VERSION ""

NS_ :

BS_:

BU_: EBCM EON CAM PCM EPS VSA SCM BDY XXX

BO_ 57 XXX_1: 3 XXX

BO_ 148 XXX_2: 8 XXX

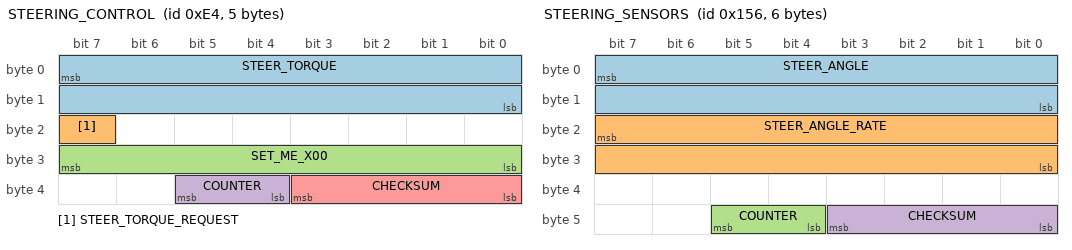
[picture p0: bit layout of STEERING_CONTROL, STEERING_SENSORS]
BO_ 228 STEERING_CONTROL: 5 CAM
 SG_ STEER_TORQUE : 7|16@0- (1,0) [-3840|3840] "" EPS
 SG_ STEER_TORQUE_REQUEST : 23|1@0+ (1,0) [0|1] "" EPS
 SG_ SET_ME_X00 : 31|8@0+ (1,0) [0|0] "" EPS
 SG_ COUNTER : 37|2@0+ (1,0) [0|3] "" EPS
 SG_ CHECKSUM : 35|4@0+ (1,0) [0|3] "" EPS

BO_ 229 XXX_3: 4 XXX

BO_ 316 GAS_PEDAL: 8 PCM
 SG_ CAR_GAS : 39|8@0+ (1,0) [0|255] "" EON

BO_ 342 STEERING_SENSORS: 6 EPS
 SG_ STEER_ANGLE : 7|16@0- (-0.1,0) [-500|500] "deg" EON
 SG_ STEER_ANGLE_RATE : 23|16@0- (1,0) [-3000|3000] "deg/s" EON
 SG_ COUNTER : 45|2@0+ (1,0) [0|3] "" EON
 SG_ CHECKSUM : 43|4@0+ (1,0) [0|3] "" EON

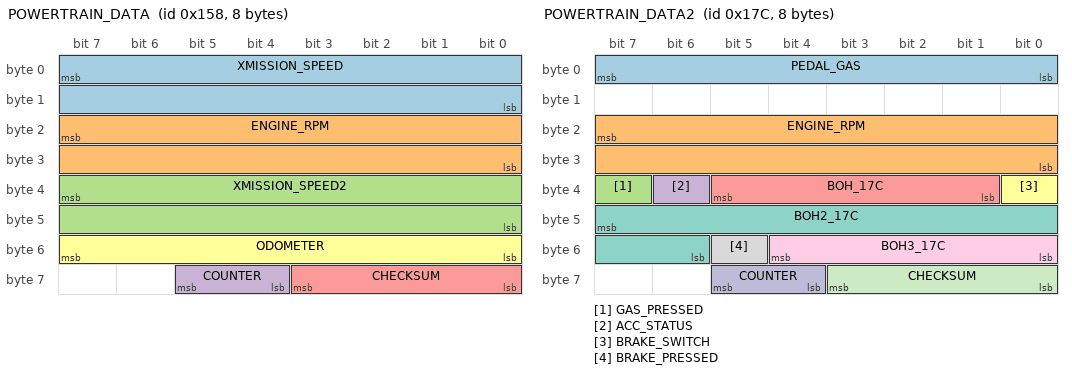
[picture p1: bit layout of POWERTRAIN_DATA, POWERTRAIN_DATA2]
BO_ 344 POWERTRAIN_DATA: 8 PCM
 SG_ XMISSION_SPEED : 7|16@0+ (0.002759506,0) [0|70] "m/s" EON
 SG_ ENGINE_RPM : 23|16@0+ (1,0) [0|15000] "rpm" EON
 SG_ XMISSION_SPEED2 : 39|16@0+ (0.002759506,0) [0|70] "m/s" EON
 SG_ COUNTER : 61|2@0+ (1,0) [0|3] "" EON
 SG_ CHECKSUM : 59|4@0+ (1,0) [0|3] "" EON
 SG_ ODOMETER : 55|8@0+ (1,0) [0|255] "" XXX

BO_ 380 POWERTRAIN_DATA2: 8 PCM
 SG_ PEDAL_GAS : 7|8@0+ (1,0) [0|255] "" EON
 SG_ ENGINE_RPM : 23|16@0+ (1,0) [0|15000] "rpm" EON
 SG_ GAS_PRESSED : 39|1@0+ (1,0) [0|1] "" EON
 SG_ ACC_STATUS : 38|1@0+ (1,0) [0|1] "rpm" EON
 SG_ BOH_17C : 37|5@0+ (1,0) [0|1] "rpm" EON
 SG_ BRAKE_SWITCH : 32|1@0+ (1,0) [0|1] "rpm" EON
 SG_ BOH2_17C : 47|10@0+ (1,0) [0|1] "rpm" EON
 SG_ BRAKE_PRESSED : 53|1@0+ (1,0) [0|1] "" EON
 SG_ BOH3_17C : 52|5@0+ (1,0) [0|1] "rpm" EON
 SG_ COUNTER : 61|2@0+ (1,0) [0|3] "" EON
 SG_ CHECKSUM : 59|4@0+ (1,0) [0|3] "" EON

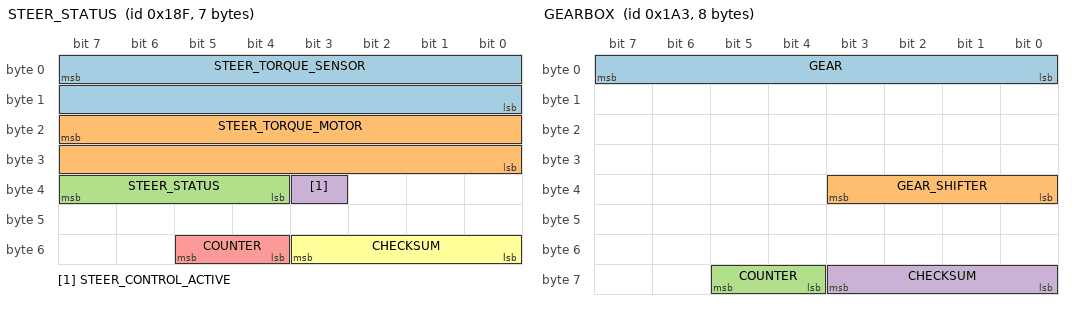
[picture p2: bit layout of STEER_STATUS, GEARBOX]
BO_ 399 STEER_STATUS: 7 EPS
 SG_ STEER_TORQUE_SENSOR : 7|16@0- (1,0) [-31000|31000] "tbd" EON
 SG_ STEER_TORQUE_MOTOR : 23|16@0- (1,0) [-31000|31000] "tbd" EON
 SG_ STEER_STATUS : 39|4@0+ (1,0) [0|15] "" EON
 SG_ STEER_CONTROL_ACTIVE : 35|1@0+ (1,0) [0|1] "" EON
 SG_ COUNTER : 53|2@0+ (1,0) [0|3] "" EON
 SG_ CHECKSUM : 51|4@0+ (1,0) [0|3] "" EON

BO_ 411 XXX_4: 5 XXX

BO_ 419 GEARBOX: 8 PCM
 SG_ GEAR : 7|8@0+ (1,0) [0|256] "" EON
 SG_ GEAR_SHIFTER : 35|4@0+ (1,0) [0|15] "" EON
 SG_ COUNTER : 61|2@0+ (1,0) [0|3] "" EON
 SG_ CHECKSUM : 59|4@0+ (1,0) [0|3] "" EON

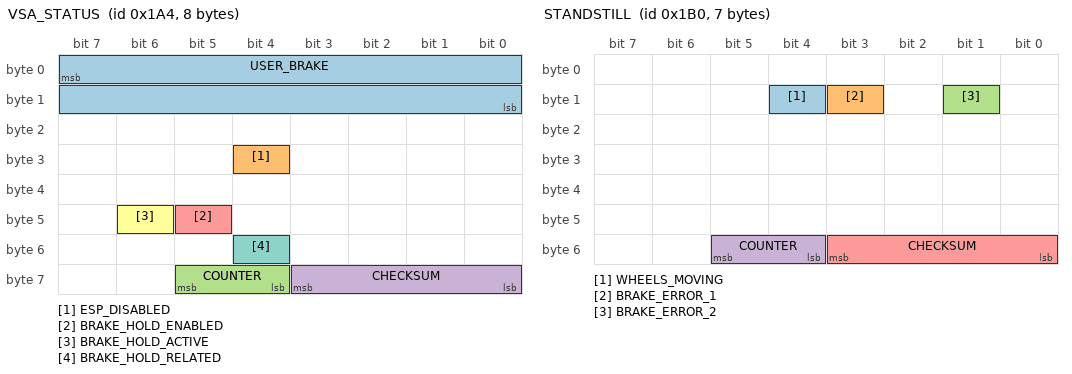
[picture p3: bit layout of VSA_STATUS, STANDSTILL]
BO_ 420 VSA_STATUS: 8 VSA
 SG_ USER_BRAKE : 7|16@0+ (0.015625,-1.609375) [0|1000] "" EON
 SG_ ESP_DISABLED : 28|1@0+ (1,0) [0|1] "" EON
 SG_ COUNTER : 61|2@0+ (1,0) [0|3] "" EON
 SG_ CHECKSUM : 59|4@0+ (1,0) [0|3] "" EON
 SG_ BRAKE_HOLD_ENABLED : 45|1@0+ (1,0) [0|1] "" XXX
 SG_ BRAKE_HOLD_ACTIVE : 46|1@0+ (1,0) [0|1] "" XXX
 SG_ BRAKE_HOLD_RELATED : 52|1@0+ (1,0) [0|1] "" XXX

BO_ 427 XXX_5: 3 XXX

BO_ 432 STANDSTILL: 7 VSA
 SG_ WHEELS_MOVING : 12|1@0+ (1,0) [0|1] "" EON
 SG_ BRAKE_ERROR_1 : 11|1@0+ (1,0) [0|1] "" EON
 SG_ BRAKE_ERROR_2 : 9|1@0+ (1,0) [0|1] "" EON
 SG_ COUNTER : 53|2@0+ (1,0) [0|3] "" EON
 SG_ CHECKSUM : 51|4@0+ (1,0) [0|3] "" EON

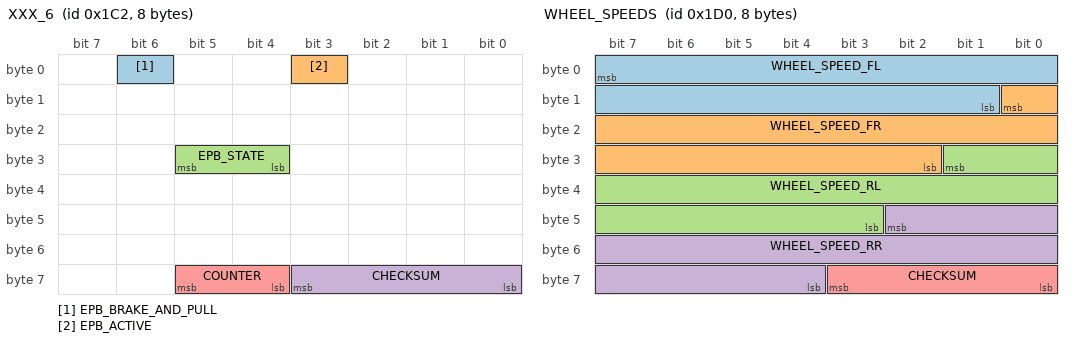
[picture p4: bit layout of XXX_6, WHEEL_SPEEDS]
BO_ 450 XXX_6: 8 XXX
 SG_ EPB_BRAKE_AND_PULL : 6|1@0+ (1,0) [0|1] "" XXX
 SG_ EPB_ACTIVE : 3|1@0+ (1,0) [0|1] "" XXX
 SG_ EPB_STATE : 29|2@0+ (1,0) [0|1] "" XXX
 SG_ CHECKSUM : 59|4@0+ (1,0) [0|15] "" XXX
 SG_ COUNTER : 61|2@0+ (1,0) [0|3] "" XXX

BO_ 463 XXX_7: 8 XXX

BO_ 464 WHEEL_SPEEDS: 8 VSA
 SG_ WHEEL_SPEED_FL : 7|15@0+ (0.002759506,0) [0|70] "m/s" EON
 SG_ WHEEL_SPEED_FR : 8|15@0+ (0.002759506,0) [0|70] "m/s" EON
 SG_ WHEEL_SPEED_RL : 25|15@0+ (0.002759506,0) [0|70] "m/s" EON
 SG_ WHEEL_SPEED_RR : 42|15@0+ (0.002759506,0) [0|70] "m/s" EON
 SG_ CHECKSUM : 59|4@0+ (1,0) [0|3] "" EON

BO_ 476 XXX_8: 4 XXX

BO_ 490 VEHICLE_DYNAMICS: 8 VSA
 SG_ LONG_ACCEL : 23|16@0- (0.0015384,0) [-20|20] "m/s2" EON

BO_ 506 BRAKE_COMMAND: 8 CAM
 SG_ COMPUTER_BRAKE : 7|10@0+ (0.003906248,0) [0|1] "" EBCM
 SG_ ZEROS_BOH : 13|5@0+ (1,0) [0|1] "" EBCM
 SG_ COMPUTER_BRAKE_REQUEST : 8|1@0+ (1,0) [0|1] "" EBCM
 SG_ CRUISE_BOH2 : 23|3@0+ (1,0) [0|1] "" EBCM
 SG_ CRUISE_OVERRIDE : 20|1@0+ (1,0) [0|1] "" EBCM
 SG_ CRUISE_BOH3 : 19|1@0+ (1,0) [0|1] "" EBCM
 SG_ CRUISE_FAULT_CMD : 18|1@0+ (1,0) [0|1] "" EBCM
 SG_ CRUISE_CANCEL_CMD : 17|1@0+ (1,0) [0|1] "" EBCM
 SG_ COMPUTER_BRAKE_REQUEST_2 : 16|1@0+ (1,0) [0|1] "" EBCM
 SG_ CRUISE_BOH4 : 31|8@0+ (1,0) [0|1] "" EBCM
 SG_ BRAKE_LIGHTS : 39|1@0+ (1,0) [0|1] "" EBCM
 SG_ CRUISE_BOH5 : 38|7@0+ (1,0) [0|1] "" EBCM
 SG_ CHIME : 47|3@0+ (1,0) [0|7] "" EBCM
 SG_ CRUISE_BOH6 : 44|1@0+ (1,0) [0|1] "" EBCM
 SG_ FCW : 43|2@0+ (1,0) [0|3] "" EBCM
 SG_ CRUISE_BOH7 : 41|10@0+ (1,0) [0|0] "" EBCM
 SG_ COUNTER : 61|2@0+ (1,0) [0|3] "" EBCM
 SG_ CHECKSUM : 59|4@0+ (1,0) [0|3] "" EBCM

BO_ 542 XXX_9: 7 XXX

BO_ 545 XXX_10: 4 XXX

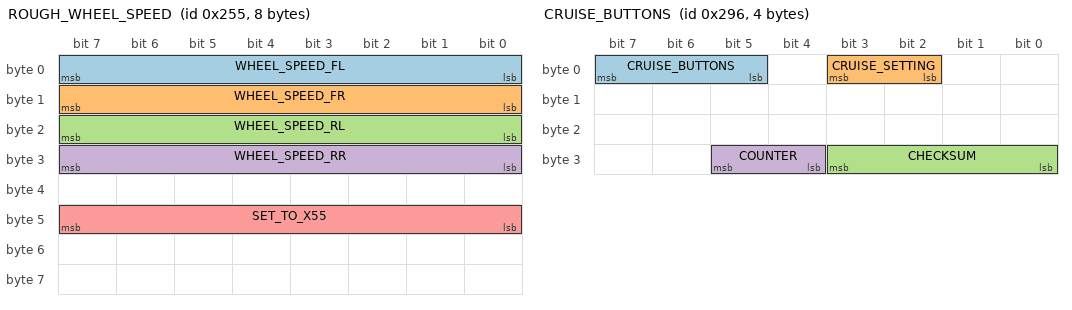
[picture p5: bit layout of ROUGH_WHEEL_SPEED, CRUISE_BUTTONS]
BO_ 597 ROUGH_WHEEL_SPEED: 8 VSA
 SG_ WHEEL_SPEED_FL : 7|8@0+ (1,0) [0|255] "mph" EON
 SG_ WHEEL_SPEED_FR : 15|8@0+ (1,0) [0|255] "mph" EON
 SG_ WHEEL_SPEED_RL : 23|8@0+ (1,0) [0|255] "mph" EON
 SG_ WHEEL_SPEED_RR : 31|8@0+ (1,0) [0|255] "mph" EON
 SG_ SET_TO_X55 : 47|8@0+ (1,0) [0|255] "" EON

BO_ 662 CRUISE_BUTTONS: 4 SCM
 SG_ CRUISE_BUTTONS : 7|3@0+ (1,0) [0|7] "" EON
 SG_ CRUISE_SETTING : 3|2@0+ (1,0) [0|3] "" EON
 SG_ CHECKSUM : 27|4@0+ (1,0) [0|3] "" EON
 SG_ COUNTER : 29|2@0+ (1,0) [0|3] "" EON

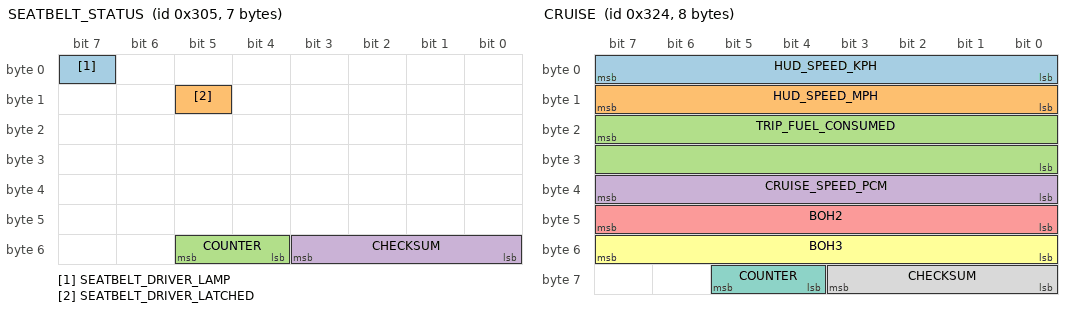
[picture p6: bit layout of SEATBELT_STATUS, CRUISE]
BO_ 773 SEATBELT_STATUS: 7 BDY
 SG_ SEATBELT_DRIVER_LAMP : 7|1@0+ (1,0) [0|1] "" EON
 SG_ SEATBELT_DRIVER_LATCHED : 13|1@0+ (1,0) [0|1] "" EON
 SG_ COUNTER : 53|2@0+ (1,0) [0|3] "" EON
 SG_ CHECKSUM : 51|4@0+ (1,0) [0|3] "" EON

BO_ 777 XXX_11: 8 XXX

BO_ 780 ACC_HUD: 8 CAM
 SG_ PCM_SPEED : 7|16@0+ (0.002763889,0) [0|100] "m/s" BDY
 SG_ PCM_GAS : 23|7@0+ (1,0) [0|127] "" BDY
 SG_ ZEROS_BOH : 16|1@0+ (1,0) [0|255] "" BDY
 SG_ CRUISE_SPEED : 31|8@0+ (1,0) [0|255] "" BDY
 SG_ DTC_MODE : 39|1@0+ (1,0) [0|1] "" BDY
 SG_ BOH : 38|1@0+ (1,0) [0|1] "" BDY
 SG_ ACC_PROBLEM : 37|1@0+ (1,0) [0|1] "" BDY
 SG_ FCM_OFF : 36|1@0+ (1,0) [0|1] "" BDY
 SG_ BOH_2 : 35|1@0+ (1,0) [0|1] "" BDY
 SG_ FCM_PROBLEM : 34|1@0+ (1,0) [0|1] "" BDY
 SG_ RADAR_OBSTRUCTED : 33|1@0+ (1,0) [0|1] "" BDY
 SG_ ENABLE_MINI_CAR : 32|1@0+ (1,0) [0|1] "" BDY
 SG_ SET_ME_X03 : 47|2@0+ (1,0) [0|3] "" BDY
 SG_ HUD_LEAD : 45|2@0+ (1,0) [0|3] "" BDY
 SG_ BOH_3 : 43|1@0+ (1,0) [0|3] "" BDY
 SG_ BOH_4 : 42|1@0+ (1,0) [0|3] "" BDY
 SG_ BOH_5 : 41|1@0+ (1,0) [0|3] "" BDY
 SG_ CRUISE_CONTROL_LABEL : 40|1@0+ (1,0) [0|3] "" BDY
 SG_ HUD_DISTANCE_3 : 52|1@0+ (1,0) [0|1] "" BDY
 SG_ COUNTER : 61|2@0+ (1,0) [0|3] "" BDY
 SG_ CHECKSUM : 59|4@0+ (1,0) [0|3] "" BDY

BO_ 795 XXX_12: 8 XXX

BO_ 800 XXX_13: 8 XXX

BO_ 804 CRUISE: 8 PCM
 SG_ HUD_SPEED_KPH : 7|8@0+ (1,0) [0|255] "kph" EON
 SG_ HUD_SPEED_MPH : 15|8@0+ (1,0) [0|255] "mph" EON
 SG_ TRIP_FUEL_CONSUMED : 23|16@0+ (1,0) [0|255] "" EON
 SG_ CRUISE_SPEED_PCM : 39|8@0+ (1,0) [0|255] "" EON
 SG_ BOH2 : 47|8@0- (1,0) [0|255] "" EON
 SG_ BOH3 : 55|8@0+ (1,0) [0|255] "" EON
 SG_ COUNTER : 61|2@0+ (1,0) [0|3] "" EON
 SG_ CHECKSUM : 59|4@0+ (1,0) [0|3] "" EON

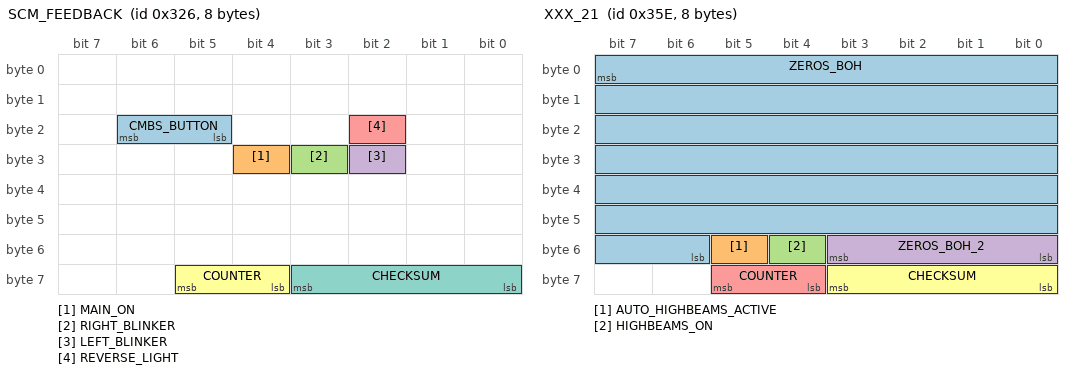
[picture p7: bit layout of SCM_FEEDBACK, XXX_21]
BO_ 806 SCM_FEEDBACK: 8 SCM
 SG_ CMBS_BUTTON : 22|2@0+ (1,0) [0|3] "" EON
 SG_ MAIN_ON : 28|1@0+ (1,0) [0|1] "" EON
 SG_ RIGHT_BLINKER : 27|1@0+ (1,0) [0|1] "" EON
 SG_ LEFT_BLINKER : 26|1@0+ (1,0) [0|1] "" EON
 SG_ REVERSE_LIGHT : 18|1@0+ (1,0) [0|1] "" EON
 SG_ COUNTER : 61|2@0+ (1,0) [0|3] "" EON
 SG_ CHECKSUM : 59|4@0+ (1,0) [0|3] "" EON

BO_ 808 XXX_14: 8 XXX

BO_ 817 XXX_15: 4 XXX

BO_ 819 XXX_16: 7 XXX

BO_ 821 XXX_17: 5 XXX

BO_ 825 XXX_18: 4 XXX

BO_ 829 LKAS_HUD: 5 CAM
 SG_ CAM_TEMP_HIGH : 7|1@0+ (1,0) [0|255] "" BDY
 SG_ BOH : 23|2@0+ (1,0) [0|4] "" BDY
 SG_ DASHED_LANES : 14|1@0+ (1,0) [0|1] "" BDY
 SG_ DTC : 13|1@0+ (1,0) [0|1] "" BDY
 SG_ LKAS_PROBLEM : 12|1@0+ (1,0) [0|1] "" BDY
 SG_ LKAS_OFF : 11|1@0+ (1,0) [0|1] "" BDY
 SG_ SOLID_LANES : 10|1@0+ (1,0) [0|1] "" BDY
 SG_ LDW_RIGHT : 9|1@0+ (1,0) [0|1] "" BDY
 SG_ STEERING_REQUIRED : 8|1@0+ (1,0) [0|1] "" BDY
 SG_ LDW_PROBLEM : 21|1@0+ (1,0) [0|1] "" BDY
 SG_ BEEP : 17|2@0+ (1,0) [0|1] "" BDY
 SG_ LDW_ON : 28|1@0+ (1,0) [0|1] "" BDY
 SG_ LDW_OFF : 27|1@0+ (1,0) [0|1] "" BDY
 SG_ CLEAN_WINDSHIELD : 26|1@0+ (1,0) [0|1] "" BDY
 SG_ SET_ME_X48 : 31|8@0+ (1,0) [0|255] "" BDY
 SG_ COUNTER : 37|2@0+ (1,0) [0|3] "" BDY
 SG_ CHECKSUM : 35|4@0+ (1,0) [0|3] "" BDY

BO_ 837 XXX_19: 5 XXX

BO_ 856 XXX_20: 7 XXX

BO_ 862 XXX_21: 8 CAM
 SG_ ZEROS_BOH : 7|50@0+ (1,0) [0|127] "" BDY
 SG_ AUTO_HIGHBEAMS_ACTIVE : 53|1@0+ (1,0) [0|1] "" XXX
 SG_ HIGHBEAMS_ON : 52|1@0+ (1,0) [0|1] "" XXX
 SG_ ZEROS_BOH_2 : 48|4@1+ (1,0) [0|15] "" XXX
 SG_ COUNTER : 61|2@0+ (1,0) [0|3] "" XXX
 SG_ CHECKSUM : 59|4@0+ (1,0) [0|15] "" XXX

BO_ 871 XXX_22: 8 XXX

BO_ 881 XXX_23: 8 XXX

BO_ 882 XXX_24: 4 XXX

BO_ 884 XXX_25: 8 XXX

BO_ 891 XXX_26: 8 XXX

BO_ 892 CRUISE_PARAMS: 8 PCM
 SG_ CRUISE_SPEED_OFFSET : 31|8@0- (0.1,0) [-128|127] "kph" EON

BO_ 905 XXX_27: 8 XXX

BO_ 923 XXX_28: 2 XXX

BO_ 927 ACC_HUD_2: 8 CAM
 SG_ ZEROS_BOH : 7|17@0+ (1,0) [0|127] "" BDY
 SG_ APPLY_BRAKES_FOR_CANC : 23|1@0+ (1,0) [0|15] "" BDY
 SG_ ZEROS_BOH2 : 31|8@0+ (1,0) [0|127] "" BDY
 SG_ RESUME_INSTRUCTION : 21|1@0+ (1,0) [0|15] "" BDY
 SG_ ACC_ALERTS : 20|5@0+ (1,0) [0|15] "" BDY
 SG_ LEAD_SPEED : 39|9@0+ (1,0) [0|127] "" BDY
 SG_ LEAD_STATE : 46|3@0+ (1,0) [0|127] "" BDY
 SG_ LEAD_DISTANCE : 43|5@0+ (1,0) [0|31] "" BDY
 SG_ ZEROS_BOH3 : 54|7@0+ (1,0) [0|127] "" BDY
 SG_ COUNTER : 61|2@0+ (1,0) [0|3] "" BDY
 SG_ CHECKSUM : 59|4@0+ (1,0) [0|3] "" BDY

BO_ 929 XXX_29: 8 XXX

BO_ 963 XXX_30: 8 XXX

BO_ 965 XXX_31: 8 XXX

BO_ 966 XXX_32: 8 XXX

BO_ 967 XXX_33: 8 XXX

BO_ 983 XXX_34: 8 XXX

BO_ 985 XXX_35: 3 XXX

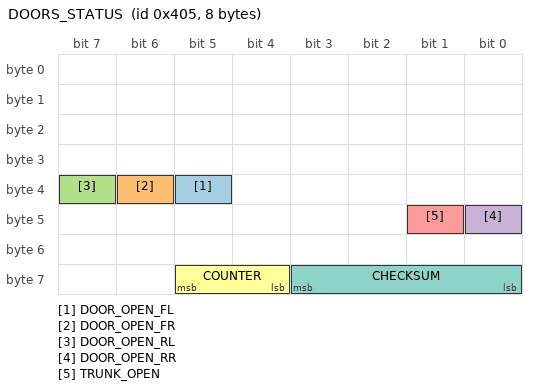
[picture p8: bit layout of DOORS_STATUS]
BO_ 1029 DOORS_STATUS: 8 BDY
 SG_ DOOR_OPEN_FL : 37|1@0+ (1,0) [0|1] "" EON
 SG_ DOOR_OPEN_FR : 38|1@0+ (1,0) [0|1] "" EON
 SG_ DOOR_OPEN_RL : 39|1@0+ (1,0) [0|1] "" EON
 SG_ DOOR_OPEN_RR : 40|1@0+ (1,0) [0|1] "" EON
 SG_ TRUNK_OPEN : 41|1@0+ (1,0) [0|1] "" EON
 SG_ COUNTER : 61|2@0+ (1,0) [0|3] "" EON
 SG_ CHECKSUM : 59|4@0+ (1,0) [0|3] "" EON

BO_ 1036 XXX_36: 8 XXX

BO_ 1052 XXX_37: 8 XXX

BO_ 1064 XXX_38: 7 XXX

BO_ 1088 XXX_39: 8 XXX

BO_ 1089 XXX_40: 8 XXX

BO_ 1092 XXX_41: 1 XXX

BO_ 1108 XXX_42: 8 XXX

BO_ 1110 XXX_43: 8 XXX

BO_ 1125 XXX_44: 8 XXX

BO_ 1296 XXX_45: 8 XXX

BO_ 1302 XXX_46: 8 XXX

BO_ 1600 XXX_47: 5 XXX

BO_ 1601 XXX_48: 8 XXX

BO_ 1612 XXX_49: 5 XXX

BO_ 1613 XXX_50: 5 XXX

BO_ 1614 XXX_51: 5 XXX

BO_ 1615 XXX_52: 8 XXX

BO_ 1616 XXX_53: 5 XXX

BO_ 1619 XXX_54: 5 XXX

BO_ 1623 XXX_55: 5 XXX

BO_ 1668 XXX_56: 5 XXX

BO_TX_BU_ 228 : EON,CAM;
BO_TX_BU_ 506 : EON,CAM;
BO_TX_BU_ 780 : EON,CAM;
BO_TX_BU_ 829 : EON,CAM;
BO_TX_BU_ 862 : EON,CAM;
BO_TX_BU_ 927 : EON,CAM;

CM_ SG_ 419 GEAR "10 = reverse, 11 = transition";
CM_ SG_ 420 BRAKE_HOLD_RELATED "On when Brake Hold engaged";
CM_ SG_ 450 EPB_STATE "3 "engaged" 2 "disengaging" 1 "engaging" 0 "disengaged"";
CM_ SG_ 490 LONG_ACCEL "wheel speed derivative, noisy and zero snapping";
CM_ SG_ 780 CRUISE_SPEED "255 = no speed";
CM_ SG_ 804 CRUISE_SPEED_PCM "255 = no speed";
CM_ SG_ 829 BEEP "beeps are pleasant, chimes are for warnings etc...";
VAL_ 399 STEER_STATUS 5 "fault" 4 "no_torque_alert_2" 2 "no_torque_alert_1" 0 "normal" ;
VAL_ 419 GEAR_SHIFTER 10 "S" 4 "D" 3 "N" 2 "R" 1 "P" ;
VAL_ 506 CHIME 4 "double_chime" 3 "single_chime" 2 "continuous_chime" 1 "repeating_chime" 0 "no_chime" ;
VAL_ 506 FCW 3 "fcw" 2 "fcw" 1 "fcw" 0 "no_fcw" ;
VAL_ 780 HUD_LEAD 3 "no_car" 2 "solid_car" 1 "dashed_car" 0 "no_car" ;
VAL_ 829 BEEP 3 "single_beep" 2 "triple_beep" 1 "repeated_beep" 0 "no_beep" ;
VAL_ 927 ACC_ALERTS 29 "esp_active_acc_canceled" 10 "b_pedal_applied" 9 "speed_too_low" 8 "speed_too_high" 7 "p_brake_applied" 6 "gear_no_d" 5 "seatbelt" 4 "too_steep_downhill" 3 "too_steep_uphill" 2 "too_close" 1 "no_vehicle_ahead" ;
CM_ "CHFFR_METRIC 342 STEER_ANGLE STEER_ANGLE 0.36 180; CHFFR_METRIC 380 ENGINE_RPM ENGINE_RPM 1 0; CHFFR_METRIC 804 ENGINE_TEMPERATURE ENGINE_TEMPERATURE 1 0";
